AUTOSAR XML (schema 4-2-2)
package /Components
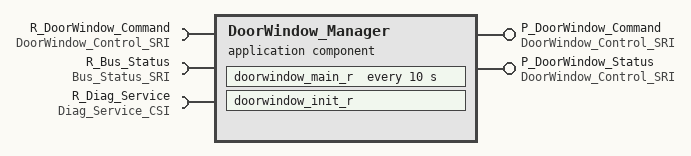
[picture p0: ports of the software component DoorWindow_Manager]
  application sw component type DoorWindow_Manager
    provide port P_DoorWindow_Command: provided-interface=DoorWindow_Control_SRI
    provide port P_DoorWindow_Status: provided-interface=DoorWindow_Control_SRI
    require port R_DoorWindow_Command: required-interface=DoorWindow_Control_SRI
    require port R_Bus_Status: required-interface=Bus_Status_SRI
    require port R_Diag_Service: required-interface=Diag_Service_CSI
    behavior DoorWindow_Manager_InternalBehavior
      data received event BusStatus_Update: start-on-event=doorwindow_main_r
      init event DoorWindow_Init: start-on-event=doorwindow_init_r
      timing event DoorWindow_Main_Cycle: start-on-event=doorwindow_main_r, period=10
      runnable doorwindow_init_r: symbol=doorwindow_init
        data-receive-point-by-values:
          access rx_bus_online_init: accessed-variable=R_Bus_Status.bus_online
        data-send-points:
          access tx_initial_door_status: accessed-variable=P_DoorWindow_Status.door_status
          access tx_initial_window_position: accessed-variable=P_DoorWindow_Status.window_position
        parameter access param_read_bus_error_count_init: accessed-parameter=R_Bus_Status.bus_error_count
        sync call scp_get_update_status_init: operation=R_Diag_Service.GetUpdateStatus, timeout=1000
      runnable doorwindow_main_r: minimum-start-interval=10, symbol=doorwindow_main
        data-receive-point-by-values:
          5 x access:
            rx_door_lock_cmd: accessed-variable=R_DoorWindow_Command.door_lock_cmd
            rx_window_move_cmd: accessed-variable=R_DoorWindow_Command.window_move_cmd
            rx_bus_online: accessed-variable=R_Bus_Status.bus_online
            rx_bus_error_count: accessed-variable=R_Bus_Status.bus_error_count
            rx_bus_load: accessed-variable=R_Bus_Status.bus_load
        data-send-points:
          4 x access:
            tx_door_lock_cmd: accessed-variable=P_DoorWindow_Command.door_lock_cmd
            tx_window_move_cmd: accessed-variable=P_DoorWindow_Command.window_move_cmd
            tx_door_status: accessed-variable=P_DoorWindow_Status.door_status
            tx_window_position: accessed-variable=P_DoorWindow_Status.window_position
        parameter access param_read_bus_load_main: accessed-parameter=R_Bus_Status.bus_load
        sync call scp_get_update_status_main: operation=R_Diag_Service.GetUpdateStatus, timeout=2000
